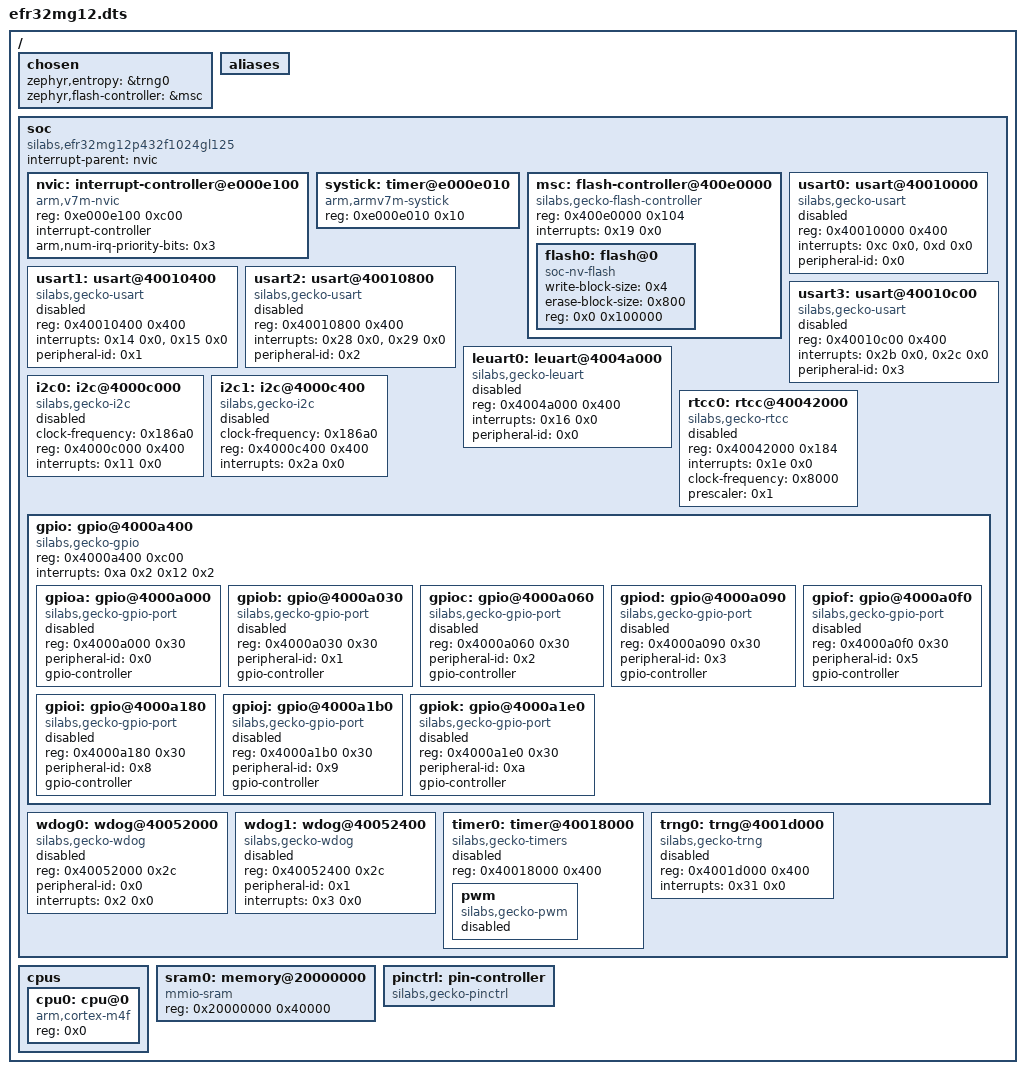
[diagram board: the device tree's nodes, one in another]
/dts-v1/;

/ {
	#address-cells = < 0x1 >;
	#size-cells = < 0x1 >;
	chosen {
		zephyr,entropy = &trng0;
		zephyr,flash-controller = &msc;
	};
	aliases {
	};
	soc {
		#address-cells = < 0x1 >;
		#size-cells = < 0x1 >;
		compatible = "silabs,efr32mg12p432f1024gl125", "silabs,efr32mg12p", "silabs,efr32", "simple-bus";
		interrupt-parent = < &nvic >;
		ranges;
		nvic: interrupt-controller@e000e100 {
			#address-cells = < 0x1 >;
			compatible = "arm,v7m-nvic";
			reg = < 0xe000e100 0xc00 >;
			interrupt-controller;
			#interrupt-cells = < 0x2 >;
			arm,num-irq-priority-bits = < 0x3 >;
			phandle = < 0x1 >;
		};
		systick: timer@e000e010 {
			compatible = "arm,armv7m-systick";
			reg = < 0xe000e010 0x10 >;
		};
		msc: flash-controller@400e0000 {
			compatible = "silabs,gecko-flash-controller";
			reg = < 0x400e0000 0x104 >;
			interrupts = < 0x19 0x0 >;
			#address-cells = < 0x1 >;
			#size-cells = < 0x1 >;
			flash0: flash@0 {
				compatible = "soc-nv-flash";
				write-block-size = < 0x4 >;
				erase-block-size = < 0x800 >;
				reg = < 0x0 0x100000 >;
			};
		};
		usart0: usart@40010000 {
			compatible = "silabs,gecko-usart";
			reg = < 0x40010000 0x400 >;
			interrupts = < 0xc 0x0 >, < 0xd 0x0 >;
			interrupt-names = "rx", "tx";
			peripheral-id = < 0x0 >;
			status = "disabled";
		};
		usart1: usart@40010400 {
			compatible = "silabs,gecko-usart";
			reg = < 0x40010400 0x400 >;
			interrupts = < 0x14 0x0 >, < 0x15 0x0 >;
			interrupt-names = "rx", "tx";
			peripheral-id = < 0x1 >;
			status = "disabled";
		};
		usart2: usart@40010800 {
			compatible = "silabs,gecko-usart";
			reg = < 0x40010800 0x400 >;
			interrupts = < 0x28 0x0 >, < 0x29 0x0 >;
			interrupt-names = "rx", "tx";
			peripheral-id = < 0x2 >;
			status = "disabled";
		};
		usart3: usart@40010c00 {
			compatible = "silabs,gecko-usart";
			reg = < 0x40010c00 0x400 >;
			interrupts = < 0x2b 0x0 >, < 0x2c 0x0 >;
			interrupt-names = "rx", "tx";
			peripheral-id = < 0x3 >;
			status = "disabled";
		};
		leuart0: leuart@4004a000 {
			compatible = "silabs,gecko-leuart";
			reg = < 0x4004a000 0x400 >;
			interrupts = < 0x16 0x0 >;
			peripheral-id = < 0x0 >;
			status = "disabled";
		};
		i2c0: i2c@4000c000 {
			compatible = "silabs,gecko-i2c";
			clock-frequency = < 0x186a0 >;
			#address-cells = < 0x1 >;
			#size-cells = < 0x0 >;
			reg = < 0x4000c000 0x400 >;
			interrupts = < 0x11 0x0 >;
			status = "disabled";
		};
		i2c1: i2c@4000c400 {
			compatible = "silabs,gecko-i2c";
			clock-frequency = < 0x186a0 >;
			#address-cells = < 0x1 >;
			#size-cells = < 0x0 >;
			reg = < 0x4000c400 0x400 >;
			interrupts = < 0x2a 0x0 >;
			status = "disabled";
		};
		rtcc0: rtcc@40042000 {
			compatible = "silabs,gecko-rtcc";
			reg = < 0x40042000 0x184 >;
			interrupts = < 0x1e 0x0 >;
			clock-frequency = < 0x8000 >;
			prescaler = < 0x1 >;
			status = "disabled";
		};
		gpio: gpio@4000a400 {
			compatible = "silabs,gecko-gpio";
			reg = < 0x4000a400 0xc00 >;
			interrupts = < 0xa 0x2 0x12 0x2 >;
			interrupt-names = "GPIO_EVEN", "GPIO_ODD";
			ranges;
			#address-cells = < 0x1 >;
			#size-cells = < 0x1 >;
			gpioa: gpio@4000a000 {
				compatible = "silabs,gecko-gpio-port";
				reg = < 0x4000a000 0x30 >;
				peripheral-id = < 0x0 >;
				gpio-controller;
				#gpio-cells = < 0x2 >;
				status = "disabled";
			};
			gpiob: gpio@4000a030 {
				compatible = "silabs,gecko-gpio-port";
				reg = < 0x4000a030 0x30 >;
				peripheral-id = < 0x1 >;
				gpio-controller;
				#gpio-cells = < 0x2 >;
				status = "disabled";
			};
			gpioc: gpio@4000a060 {
				compatible = "silabs,gecko-gpio-port";
				reg = < 0x4000a060 0x30 >;
				peripheral-id = < 0x2 >;
				gpio-controller;
				#gpio-cells = < 0x2 >;
				status = "disabled";
			};
			gpiod: gpio@4000a090 {
				compatible = "silabs,gecko-gpio-port";
				reg = < 0x4000a090 0x30 >;
				peripheral-id = < 0x3 >;
				gpio-controller;
				#gpio-cells = < 0x2 >;
				status = "disabled";
			};
			gpiof: gpio@4000a0f0 {
				compatible = "silabs,gecko-gpio-port";
				reg = < 0x4000a0f0 0x30 >;
				peripheral-id = < 0x5 >;
				gpio-controller;
				#gpio-cells = < 0x2 >;
				status = "disabled";
			};
			gpioi: gpio@4000a180 {
				compatible = "silabs,gecko-gpio-port";
				reg = < 0x4000a180 0x30 >;
				peripheral-id = < 0x8 >;
				gpio-controller;
				#gpio-cells = < 0x2 >;
				status = "disabled";
			};
			gpioj: gpio@4000a1b0 {
				compatible = "silabs,gecko-gpio-port";
				reg = < 0x4000a1b0 0x30 >;
				peripheral-id = < 0x9 >;
				gpio-controller;
				#gpio-cells = < 0x2 >;
				status = "disabled";
			};
			gpiok: gpio@4000a1e0 {
				compatible = "silabs,gecko-gpio-port";
				reg = < 0x4000a1e0 0x30 >;
				peripheral-id = < 0xa >;
				gpio-controller;
				#gpio-cells = < 0x2 >;
				status = "disabled";
			};
		};
		wdog0: wdog@40052000 {
			compatible = "silabs,gecko-wdog";
			reg = < 0x40052000 0x2c >;
			peripheral-id = < 0x0 >;
			interrupts = < 0x2 0x0 >;
			status = "disabled";
		};
		wdog1: wdog@40052400 {
			compatible = "silabs,gecko-wdog";
			reg = < 0x40052400 0x2c >;
			peripheral-id = < 0x1 >;
			interrupts = < 0x3 0x0 >;
			status = "disabled";
		};
		timer0: timer@40018000 {
			compatible = "silabs,gecko-timers";
			reg = < 0x40018000 0x400 >;
			status = "disabled";
			pwm {
				compatible = "silabs,gecko-pwm";
				status = "disabled";
				#pwm-cells = < 0x3 >;
			};
		};
		trng0: trng@4001d000 {
			compatible = "silabs,gecko-trng";
			reg = < 0x4001d000 0x400 >;
			interrupts = < 0x31 0x0 >;
			status = "disabled";
		};
	};
	cpus {
		#address-cells = < 0x1 >;
		#size-cells = < 0x0 >;
		cpu0: cpu@0 {
			compatible = "arm,cortex-m4f";
			reg = < 0x0 >;
		};
	};
	sram0: memory@20000000 {
		compatible = "mmio-sram";
		reg = < 0x20000000 0x40000 >;
	};
	pinctrl: pin-controller {
		compatible = "silabs,gecko-pinctrl";
	};
};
